AUTOSAR XML (schema 00050)
package /SwComponentDesign
  adaptive application sw component type ExtendedVehicle
    provide port VehicleStatus: provided-interface=VehicleStatusInterface
  adaptive application sw component type WatchdogApplication
    require port VehicleStatus: required-interface=VehicleStatusInterface
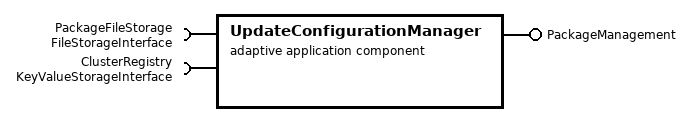
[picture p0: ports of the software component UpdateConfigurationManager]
  adaptive application sw component type UpdateConfigurationManager
    provide port PackageManagement: provided-interface=PackageManagement
    require port PackageFileStorage: required-interface=FileStorageInterface
    require port ClusterRegistry: required-interface=KeyValueStorageInterface
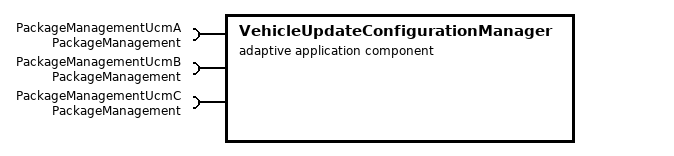
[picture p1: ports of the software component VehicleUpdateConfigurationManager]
  adaptive application sw component type VehicleUpdateConfigurationManager
    require port PackageManagementUcmA: required-interface=PackageManagement
    require port PackageManagementUcmB: required-interface=PackageManagement
    require port PackageManagementUcmC: required-interface=PackageManagement
